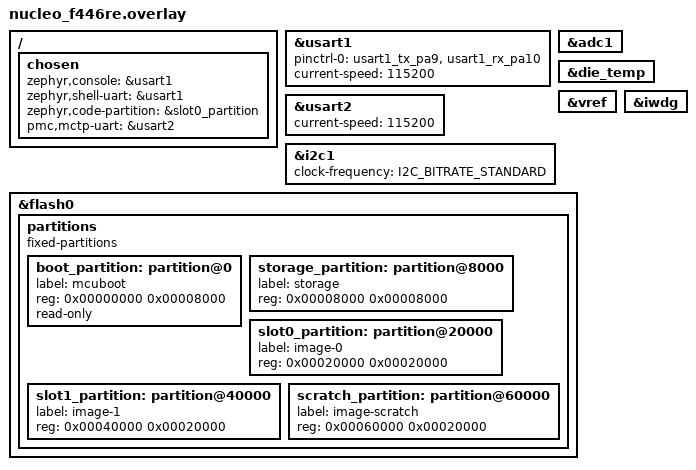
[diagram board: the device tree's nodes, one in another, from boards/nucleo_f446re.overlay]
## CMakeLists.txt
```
# pmc Zephyr application (UNTESTED - see app/README.md)
cmake_minimum_required(VERSION 3.20.0)
find_package(Zephyr REQUIRED HINTS $ENV{ZEPHYR_BASE})
project(pmc)

set(PMC_CORE ${CMAKE_CURRENT_SOURCE_DIR}/../core)

target_include_directories(app PRIVATE ${PMC_CORE}/include)
target_sources(app PRIVATE
  ${PMC_CORE}/src/crc.c
  ${PMC_CORE}/src/mctp.c
  ${PMC_CORE}/src/raslog.c
  ${PMC_CORE}/src/monitor.c
  ${PMC_CORE}/src/pldm.c
  src/main.c
  src/platform_zephyr.c
  src/mctp_uart.c
  src/raslog_nvs.c
  src/fw_mcuboot.c
  src/i2c_target.c
)
```

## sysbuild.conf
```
# Build MCUboot together with the app: `west build -b nucleo_f446re --sysbuild app`
SB_CONFIG_BOOTLOADER_MCUBOOT=y
SB_CONFIG_MCUBOOT_MODE_SWAP_SCRATCH=y
SB_CONFIG_BOOT_SIGNATURE_TYPE_ECDSA_P256=y
# Replace with your own key: imgtool keygen -k keys/pmc-ecdsa-p256.pem -t ecdsa-p256
# (the default MCUboot dev key is public - anyone can sign images with it)
SB_CONFIG_BOOT_SIGNATURE_KEY_FILE="${APP_DIR}/keys/pmc-ecdsa-p256.pem"
```

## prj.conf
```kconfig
# ---- kernel / threads ----
CONFIG_MAIN_STACK_SIZE=2048
CONFIG_HEAP_MEM_POOL_SIZE=0
CONFIG_ASSERT=y

# ---- MCTP link on USART2 (ST-LINK virtual COM port) ----
CONFIG_SERIAL=y
CONFIG_UART_INTERRUPT_DRIVEN=y
CONFIG_RING_BUFFER=y
# console + logs moved to USART1 (PA9/PA10) so they never corrupt MCTP frames
CONFIG_LOG=y
CONFIG_LOG_MODE_DEFERRED=y
CONFIG_LOG_DEFAULT_LEVEL=3

# ---- sensors: STM32 die temperature + VREFINT through ADC1 ----
CONFIG_ADC=y
CONFIG_SENSOR=y

# ---- persistent RAS log: NVS on the storage partition ----
CONFIG_FLASH=y
CONFIG_FLASH_MAP=y
CONFIG_FLASH_PAGE_LAYOUT=y
CONFIG_NVS=y

# ---- watchdog: per-thread software watchdogs backed by the IWDG ----
CONFIG_WATCHDOG=y
CONFIG_TASK_WDT=y
CONFIG_TASK_WDT_MIN_TIMEOUT=100
CONFIG_HWINFO=y

# ---- firmware update into MCUboot secondary slot ----
CONFIG_IMG_MANAGER=y
CONFIG_STREAM_FLASH=y
CONFIG_MCUBOOT_IMG_MANAGER=y
CONFIG_REBOOT=y

# ---- I2C target (register map read by the Linux hwmon driver) ----
CONFIG_I2C=y
CONFIG_I2C_TARGET=y
```

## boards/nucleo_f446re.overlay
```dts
/*
 * nucleo_f446re.overlay - pmc hardware configuration (UNTESTED)
 *
 * USART2 (PA2/PA3, ST-LINK VCP)  -> MCTP over serial to the laptop
 * USART1 (PA9/PA10)              -> console / logs (USB-UART adapter)
 * I2C1   (PB8 SCL / PB9 SDA)     -> I2C target 0x42 for the Linux hwmon driver
 * ADC1                           -> die temperature + VREFINT
 * IWDG                           -> hardware watchdog behind task_wdt
 *
 * Flash layout (STM32F446RE, 512 KiB, sectors 4x16K, 1x64K, 3x128K):
 *   0x00000 32K  MCUboot          (sectors 0-1)
 *   0x08000 32K  storage / NVS    (sectors 2-3, NVS needs >= 2 sectors)
 *   0x10000 64K  unused           (sector 4)
 *   0x20000 128K slot0 (primary)  (sector 5)
 *   0x40000 128K slot1 (secondary)(sector 6)
 *   0x60000 128K scratch          (sector 7)
 * If MCUboot does not fit in 32K with your config, use sectors 0-3 for it
 * and move storage to two 128K sectors (shrinking the image slots).
 */
/ {
	chosen {
		zephyr,console = &usart1;
		zephyr,shell-uart = &usart1;
		zephyr,code-partition = &slot0_partition;
		pmc,mctp-uart = &usart2;
	};
};

&usart1 {
	pinctrl-0 = <&usart1_tx_pa9 &usart1_rx_pa10>;
	pinctrl-names = "default";
	current-speed = <115200>;
	status = "okay";
};

&usart2 {
	current-speed = <115200>;
	status = "okay";
};

&adc1 {
	status = "okay";
};

&die_temp {
	status = "okay";
};

&vref {
	status = "okay";
};

&iwdg {
	status = "okay";
};

&i2c1 {
	status = "okay";
	clock-frequency = <I2C_BITRATE_STANDARD>;
};

&flash0 {
	/delete-node/ partitions;
	partitions {
		compatible = "fixed-partitions";
		#address-cells = <1>;
		#size-cells = <1>;

		boot_partition: partition@0 {
			label = "mcuboot";
			reg = <0x00000000 0x00008000>;
			read-only;
		};
		storage_partition: partition@8000 {
			label = "storage";
			reg = <0x00008000 0x00008000>;
		};
		slot0_partition: partition@20000 {
			label = "image-0";
			reg = <0x00020000 0x00020000>;
		};
		slot1_partition: partition@40000 {
			label = "image-1";
			reg = <0x00040000 0x00020000>;
		};
		scratch_partition: partition@60000 {
			label = "image-scratch";
			reg = <0x00060000 0x00020000>;
		};
	};
};
```

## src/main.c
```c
/*
 * main.c - pmc firmware for NUCLEO-F446RE (Zephyr). UNTESTED - see README.
 *
 * Threads:
 *   mctp_thread    (prio 5)  UART bytes -> deframer -> MCTP -> PLDM handlers
 *   monitor_thread (prio 7)  sensors every 500 ms, thresholds, RAS events,
 *                            publishes the I2C register map
 *   main           (prio 0)  boot: reset-cause logging, init, image confirm
 *
 * Every worker thread owns a task-watchdog channel. If a thread stops
 * feeding it (deadlock, infinite loop), the IWDG resets the MCU and the
 * reset cause is logged as a fatal RAS event on the next boot.
 *
 * Concurrency: the PLDM layer reads monitor state and the RAS log, which
 * the monitor thread writes, so both are guarded by pmc_lock.
 */
#include <zephyr/drivers/hwinfo.h>
#include <zephyr/drivers/watchdog.h>
#include <zephyr/kernel.h>
#include <zephyr/logging/log.h>
#include <zephyr/task_wdt/task_wdt.h>

#include "pmc_app.h"

LOG_MODULE_REGISTER(pmc, LOG_LEVEL_INF);

K_MUTEX_DEFINE(pmc_lock);

static pmc_mctp mctp;
static pmc_mctp_deframer deframer;
static pmc_raslog raslog;
static pmc_monitor monitor;
static pmc_pldm pldm;

#define MCTP_STACK 3072
#define MON_STACK  2048

static void log_reset_cause(uint32_t boot)
{
	uint32_t cause = 0;

	if (hwinfo_get_reset_cause(&cause) != 0)
		return;
	if (cause & RESET_WATCHDOG)
		pmc_raslog_add(&raslog, RAS_SRC_WATCHDOG, RAS_SEV_FATAL, 0x0001, cause);
	else if (cause & RESET_BROWNOUT)
		pmc_raslog_add(&raslog, RAS_SRC_BOOT, RAS_SEV_RECOVERABLE, 0x0002, cause);
	else
		pmc_raslog_add(&raslog, RAS_SRC_BOOT, RAS_SEV_INFO, 0x0001, boot);
	hwinfo_clear_reset_cause();
}

static void mctp_rx_locked(pmc_mctp *m, uint8_t src, uint8_t tag, int to,
			   const uint8_t *msg, size_t len)
{
	k_mutex_lock(&pmc_lock, K_FOREVER);
	pmc_rx_dispatch(m, src, tag, to, msg, len);
	k_mutex_unlock(&pmc_lock);
}

static void mctp_thread(void *a, void *b, void *c)
{
	int wdt = task_wdt_add(2000, NULL, NULL);
	uint8_t buf[64];

	ARG_UNUSED(a); ARG_UNUSED(b); ARG_UNUSED(c);
	for (;;) {
		size_t n = pmc_uart_rx(buf, sizeof(buf), K_MSEC(500));

		for (size_t i = 0; i < n; i++) {
			int plen = pmc_mctp_deframer_feed(&deframer, buf[i]);
			if (plen > 0)
				pmc_mctp_rx_packet(&mctp, deframer.buf, (size_t)plen);
		}
		task_wdt_feed(wdt);
	}
}

static void monitor_thread(void *a, void *b, void *c)
{
	int wdt = task_wdt_add(3000, NULL, NULL);
	uint8_t regs[PMC_REGMAP_SIZE];

	ARG_UNUSED(a); ARG_UNUSED(b); ARG_UNUSED(c);
	for (;;) {
		k_mutex_lock(&pmc_lock, K_FOREVER);
		pmc_monitor_poll(&monitor);
		pmc_regmap_snapshot(&monitor, regs);
		k_mutex_unlock(&pmc_lock);
		pmc_i2c_publish(regs);
		task_wdt_feed(wdt);
		k_sleep(K_MSEC(500));
	}
}

K_THREAD_STACK_DEFINE(mctp_stack, MCTP_STACK);
K_THREAD_STACK_DEFINE(mon_stack, MON_STACK);
static struct k_thread mctp_tid, mon_tid;

int main(void)
{
	const struct device *hw_wdt = DEVICE_DT_GET_OR_NULL(DT_NODELABEL(iwdg));
	pmc_ras_backend be;
	uint32_t boot = 0;

	LOG_INF("pmc starting");
	if (task_wdt_init(hw_wdt) != 0)
		LOG_ERR("task watchdog init failed");

	if (pmc_nvs_backend(&be, &boot) != 0 || pmc_raslog_init(&raslog, &be, boot) != PMC_OK) {
		LOG_ERR("RAS log unavailable");
	}
	log_reset_cause(boot);

	pmc_monitor_init(&monitor, &raslog);
	pmc_mctp_deframer_init(&deframer);
	pmc_mctp_init(&mctp, 0, pmc_uart_tx, NULL, mctp_rx_locked, &pldm);
	pmc_pldm_init(&pldm, &mctp, &monitor, &raslog, &pmc_fw_mcuboot);
	pldm.link = &deframer;

	if (pmc_uart_init() != 0)
		LOG_ERR("MCTP UART init failed");
	if (pmc_i2c_target_init() != 0)
		LOG_WRN("I2C target unavailable");

	k_thread_create(&mon_tid, mon_stack, MON_STACK, monitor_thread, NULL, NULL, NULL,
			7, 0, K_NO_WAIT);
	k_thread_create(&mctp_tid, mctp_stack, MCTP_STACK, mctp_thread, NULL, NULL, NULL,
			5, 0, K_NO_WAIT);

	/* A freshly updated image runs in MCUboot "test" mode. Confirm it only
	 * after it has proved itself; otherwise the next reset rolls back. */
	k_sleep(K_SECONDS(10));
	k_mutex_lock(&pmc_lock, K_FOREVER);
	pmc_fw_confirm_if_healthy(&raslog);
	k_mutex_unlock(&pmc_lock);
	return 0;
}
```

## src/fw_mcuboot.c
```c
/*
 * fw_mcuboot.c - PLDM firmware update backend on MCUboot (UNTESTED)
 *
 *  begin/write : stream the image into the secondary slot (flash_img)
 *  verify      : sanity-check the MCUboot image header here; the real
 *                ECDSA-P256 signature check is done by MCUboot at reboot,
 *                which refuses to swap in an image it cannot verify
 *  apply       : boot_request_upgrade(BOOT_UPGRADE_TEST) - one trial boot
 *  activate    : reboot (after the PLDM response has been sent)
 *
 * After the trial boot the new image must call boot_write_img_confirmed();
 * if it crashes or the watchdog fires first, MCUboot swaps back.
 */
#include <zephyr/dfu/flash_img.h>
#include <zephyr/dfu/mcuboot.h>
#include <zephyr/kernel.h>
#include <zephyr/logging/log.h>
#include <zephyr/storage/flash_map.h>
#include <zephyr/sys/reboot.h>

#include "pmc_app.h"

LOG_MODULE_REGISTER(pmc_fw, LOG_LEVEL_INF);

#define MCUBOOT_IMAGE_MAGIC 0x96f3b83dU

static struct flash_img_context img;
static uint32_t expected;

static pmc_err_t fw_begin(void *ctx, uint32_t size)
{
	ARG_UNUSED(ctx);
	if (size > FIXED_PARTITION_SIZE(slot1_partition))
		return PMC_E_INVAL;
	if (flash_img_init(&img) != 0)
		return PMC_E_IO;
	expected = size;
	return PMC_OK;
}

static pmc_err_t fw_write(void *ctx, uint32_t off, const uint8_t *data, size_t len)
{
	ARG_UNUSED(ctx);
	/* flash_img writes sequentially; the FD always requests in order */
	if (off != flash_img_bytes_written(&img))
		return PMC_E_INVAL;
	return flash_img_buffered_write(&img, data, len, off + len == expected) == 0
	       ? PMC_OK : PMC_E_IO;
}

static void reboot_work(struct k_work *w)
{
	ARG_UNUSED(w);
	sys_reboot(SYS_REBOOT_COLD);
}
static K_WORK_DELAYABLE_DEFINE(reboot_dwork, reboot_work);

static pmc_err_t fw_verify(void *ctx)
{
	const struct flash_area *fa;
	uint32_t magic = 0;

	ARG_UNUSED(ctx);
	if (flash_img_bytes_written(&img) != expected)
		return PMC_E_STATE;
	if (flash_area_open(FIXED_PARTITION_ID(slot1_partition), &fa))
		return PMC_E_IO;
	flash_area_read(fa, 0, &magic, sizeof(magic));
	flash_area_close(fa);
	if (magic != MCUBOOT_IMAGE_MAGIC) {
		LOG_ERR("not an MCUboot image (magic %08x)", magic);
		return PMC_E_CRC;
	}
	return PMC_OK;
}

static pmc_err_t fw_apply(void *ctx)
{
	ARG_UNUSED(ctx);
	return boot_request_upgrade(BOOT_UPGRADE_TEST) == 0 ? PMC_OK : PMC_E_IO;
}

static pmc_err_t fw_activate(void *ctx)
{
	ARG_UNUSED(ctx);
	/* give the ActivateFirmware response time to leave the UART */
	k_work_schedule(&reboot_dwork, K_MSEC(500));
	return PMC_OK;
}

const pmc_fw_backend pmc_fw_mcuboot = {
	fw_begin, fw_write, fw_verify, fw_apply, fw_activate, NULL
};

void pmc_fw_confirm_if_healthy(pmc_raslog *log)
{
	pmc_ras_record r;

	if (boot_is_img_confirmed())
		return;
	/* "healthy": we got this far (threads alive, no fatal event this boot) */
	if (log && pmc_raslog_get(log, 0, &r) == PMC_OK &&
	    r.severity == RAS_SEV_FATAL && r.boot_count == log->boot_count) {
		LOG_WRN("fatal event in trial image - not confirming, will roll back");
		return;
	}
	if (boot_write_img_confirmed() == 0) {
		LOG_INF("new image confirmed");
		pmc_raslog_add(log, RAS_SRC_FWUP, RAS_SEV_INFO, 0x0100, 0);
	}
}
```

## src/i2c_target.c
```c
/*
 * i2c_target.c - SMBus-style register file at address 0x42 (UNTESTED)
 *
 * Protocol (what the Linux driver's i2c_smbus_read_*_data() produces):
 *   START addr+W  reg  RESTART addr+R  data0 data1 ...  STOP
 * The first written byte sets the register pointer; reads auto-increment.
 *
 * The monitor thread publishes a fresh snapshot every 500 ms. The ISR only
 * reads from the "front" buffer, so it never sees a half-updated file.
 */
#include <zephyr/device.h>
#include <zephyr/drivers/i2c.h>
#include <zephyr/kernel.h>

#include "pmc_app.h"

#define PMC_I2C_ADDR 0x42

static const struct device *const i2c = DEVICE_DT_GET(DT_NODELABEL(i2c1));
static uint8_t bufs[2][PMC_REGMAP_SIZE];
static atomic_t front;           /* index of the buffer the ISR reads */
static uint8_t ptr;
static bool ptr_set;

void pmc_i2c_publish(const uint8_t regs[PMC_REGMAP_SIZE])
{
	int back = !atomic_get(&front);
	memcpy(bufs[back], regs, PMC_REGMAP_SIZE);
	atomic_set(&front, back);
}

static uint8_t reg_byte(uint8_t r)
{
	return r < PMC_REGMAP_SIZE ? bufs[atomic_get(&front)][r] : 0xFF;
}

static int t_write_requested(struct i2c_target_config *cfg)
{
	ARG_UNUSED(cfg);
	ptr_set = false;
	return 0;
}

static int t_write_received(struct i2c_target_config *cfg, uint8_t val)
{
	ARG_UNUSED(cfg);
	if (!ptr_set) {
		ptr = val;
		ptr_set = true;
	}
	/* register file is read-only: further written bytes are ignored */
	return 0;
}

static int t_read_requested(struct i2c_target_config *cfg, uint8_t *val)
{
	ARG_UNUSED(cfg);
	*val = reg_byte(ptr);
	return 0;
}

static int t_read_processed(struct i2c_target_config *cfg, uint8_t *val)
{
	ARG_UNUSED(cfg);
	ptr++;
	*val = reg_byte(ptr);
	return 0;
}

static int t_stop(struct i2c_target_config *cfg)
{
	ARG_UNUSED(cfg);
	return 0;
}

static const struct i2c_target_callbacks cbs = {
	.write_requested = t_write_requested,
	.write_received = t_write_received,
	.read_requested = t_read_requested,
	.read_processed = t_read_processed,
	.stop = t_stop,
};

static struct i2c_target_config tcfg = {
	.address = PMC_I2C_ADDR,
	.callbacks = &cbs,
};

int pmc_i2c_target_init(void)
{
	if (!device_is_ready(i2c))
		return -ENODEV;
	return i2c_target_register(i2c, &tcfg);
}
```

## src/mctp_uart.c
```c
/*
 * mctp_uart.c - interrupt-driven UART for the MCTP serial binding (UNTESTED)
 *
 * RX: the ISR moves bytes from the UART FIFO into a ring buffer and gives a
 * semaphore; the MCTP thread drains it. Nothing protocol-related happens
 * in interrupt context.
 * TX: polled output - at 115200 baud a 140-byte frame takes ~12 ms, which
 * is fine for a management link. Switch to async/DMA for higher rates.
 */
#include <zephyr/device.h>
#include <zephyr/drivers/uart.h>
#include <zephyr/kernel.h>
#include <zephyr/sys/ring_buffer.h>

#include "pmc_app.h"

static const struct device *const uart = DEVICE_DT_GET(DT_CHOSEN(pmc_mctp_uart));
RING_BUF_DECLARE(rx_ring, 512);
static K_SEM_DEFINE(rx_sem, 0, 1);
static uint32_t rx_overruns;

static void uart_isr(const struct device *dev, void *user)
{
	uint8_t buf[32];

	ARG_UNUSED(user);
	if (!uart_irq_update(dev))
		return;
	while (uart_irq_rx_ready(dev)) {
		int n = uart_fifo_read(dev, buf, sizeof(buf));
		if (n <= 0)
			break;
		if (ring_buf_put(&rx_ring, buf, (uint32_t)n) < (uint32_t)n)
			rx_overruns++;           /* thread too slow: frame will fail FCS */
		k_sem_give(&rx_sem);
	}
}

int pmc_uart_init(void)
{
	if (!device_is_ready(uart))
		return -ENODEV;
	uart_irq_callback_user_data_set(uart, uart_isr, NULL);
	uart_irq_rx_enable(uart);
	return 0;
}

void pmc_uart_tx(void *arg, const uint8_t *frame, size_t len)
{
	ARG_UNUSED(arg);
	for (size_t i = 0; i < len; i++)
		uart_poll_out(uart, frame[i]);
}

size_t pmc_uart_rx(uint8_t *buf, size_t max, k_timeout_t timeout)
{
	uint32_t n = ring_buf_get(&rx_ring, buf, (uint32_t)max);

	if (n)
		return n;
	if (k_sem_take(&rx_sem, timeout) != 0)
		return 0;
	return ring_buf_get(&rx_ring, buf, (uint32_t)max);
}
```

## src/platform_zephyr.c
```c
/* platform_zephyr.c - core platform hooks on Zephyr (UNTESTED) */
#include <zephyr/device.h>
#include <zephyr/drivers/sensor.h>
#include <zephyr/kernel.h>

#include "pmc/monitor.h"

static const struct device *const die_temp = DEVICE_DT_GET(DT_NODELABEL(die_temp));
static const struct device *const vref = DEVICE_DT_GET(DT_NODELABEL(vref));

uint32_t pmc_platform_uptime_ms(void)
{
	return k_uptime_get_32();
}

pmc_err_t pmc_platform_sensor_read(uint8_t id, int32_t *value)
{
	struct sensor_value v;

	if (id == PMC_SENSOR_TEMP) {
		if (!device_is_ready(die_temp) || sensor_sample_fetch(die_temp) ||
		    sensor_channel_get(die_temp, SENSOR_CHAN_DIE_TEMP, &v))
			return PMC_E_IO;
		/* degC -> 0.1 degC */
		*value = v.val1 * 10 + v.val2 / 100000;
		return PMC_OK;
	}
	if (id == PMC_SENSOR_VOLT) {
		/* VREFINT gives the actual VDDA in mV */
		if (!device_is_ready(vref) || sensor_sample_fetch(vref) ||
		    sensor_channel_get(vref, SENSOR_CHAN_VOLTAGE, &v))
			return PMC_E_IO;
		*value = v.val1 * 1000 + v.val2 / 1000;
		return PMC_OK;
	}
	return PMC_E_INVAL;
}
```

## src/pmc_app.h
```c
/* pmc_app.h - shared declarations between the Zephyr app modules */
#ifndef PMC_APP_H
#define PMC_APP_H

#include <zephyr/kernel.h>

#include "pmc/pldm.h"

/* mctp_uart.c */
int pmc_uart_init(void);
void pmc_uart_tx(void *arg, const uint8_t *frame, size_t len);
/* blocks until bytes arrive; returns count copied into buf */
size_t pmc_uart_rx(uint8_t *buf, size_t max, k_timeout_t timeout);

/* raslog_nvs.c */
int pmc_nvs_backend(pmc_ras_backend *be, uint32_t *boot_count);

/* fw_mcuboot.c */
extern const pmc_fw_backend pmc_fw_mcuboot;
void pmc_fw_confirm_if_healthy(pmc_raslog *log);

/* i2c_target.c */
int pmc_i2c_target_init(void);
void pmc_i2c_publish(const uint8_t regs[PMC_REGMAP_SIZE]);

#endif
```

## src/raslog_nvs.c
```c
/*
 * raslog_nvs.c - RAS log backend on Zephyr NVS (UNTESTED)
 *
 * STM32F4 flash can only be erased in whole sectors (16-128 KiB), so the
 * core's "write slot N" cannot be done in place. NVS (a log-structured
 * key-value store) handles erase, wear levelling and power-cut safety for
 * us: slot N is stored under NVS id N + 1, the boot counter under id 1000.
 */
#include <zephyr/device.h>
#include <zephyr/drivers/flash.h>
#include <zephyr/fs/nvs.h>
#include <zephyr/storage/flash_map.h>

#include "pmc_app.h"

#define RAS_SLOTS     32
#define ID_BOOTCOUNT  1000

static struct nvs_fs fs;

static pmc_err_t nvs_read_slot(void *ctx, uint32_t off, uint8_t *buf, size_t len)
{
	ssize_t r;

	ARG_UNUSED(ctx);
	r = nvs_read(&fs, (uint16_t)(off / PMC_RAS_REC_SIZE + 1), buf, len);
	if (r == -ENOENT) {
		memset(buf, 0xFF, len);          /* never written == erased */
		return PMC_OK;
	}
	return r == (ssize_t)len ? PMC_OK : PMC_E_IO;
}

static pmc_err_t nvs_write_slot(void *ctx, uint32_t off, const uint8_t *buf, size_t len)
{
	ARG_UNUSED(ctx);
	return nvs_write(&fs, (uint16_t)(off / PMC_RAS_REC_SIZE + 1), buf, len) >= 0
	       ? PMC_OK : PMC_E_IO;
}

int pmc_nvs_backend(pmc_ras_backend *be, uint32_t *boot_count)
{
	struct flash_pages_info info;
	uint32_t boots = 0;

	fs.flash_device = FIXED_PARTITION_DEVICE(storage_partition);
	if (!device_is_ready(fs.flash_device))
		return -ENODEV;
	fs.offset = FIXED_PARTITION_OFFSET(storage_partition);
	if (flash_get_page_info_by_offs(fs.flash_device, fs.offset, &info))
		return -EIO;
	fs.sector_size = (uint16_t)info.size;   /* 16 KiB on sectors 2-3 */
	fs.sector_count = FIXED_PARTITION_SIZE(storage_partition) / info.size;
	if (nvs_mount(&fs))
		return -EIO;

	if (nvs_read(&fs, ID_BOOTCOUNT, &boots, sizeof(boots)) != sizeof(boots))
		boots = 0;
	boots++;
	nvs_write(&fs, ID_BOOTCOUNT, &boots, sizeof(boots));
	*boot_count = boots;

	be->read = nvs_read_slot;
	be->write = nvs_write_slot;
	be->ctx = NULL;
	be->slots = RAS_SLOTS;
	return 0;
}
```
